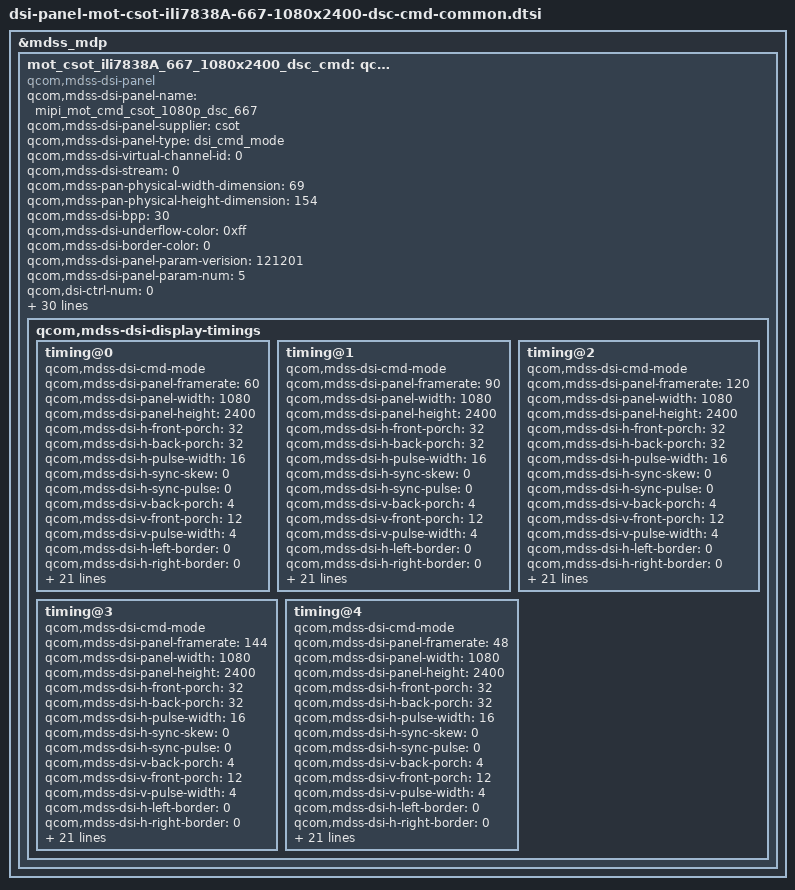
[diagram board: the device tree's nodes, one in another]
/* Copyright (c) 2019-2020, The Linux Foundation. All rights reserved.
 *
 * This program is free software; you can redistribute it and/or modify
 * it under the terms of the GNU General Public License version 2 and
 * only version 2 as published by the Free Software Foundation.
 *
 * This program is distributed in the hope that it will be useful,
 * but WITHOUT ANY WARRANTY; without even the implied warranty of
 * MERCHANTABILITY or FITNESS FOR A PARTICULAR PURPOSE.  See the
 * GNU General Public License for more details.
 */
&mdss_mdp {
mot_csot_ili7838A_667_1080x2400_dsc_cmd: qcom,mdss_dsi_mot_csot_ili7838A_667_1080x2400_dsc_cmd {
compatible = "qcom,mdss-dsi-panel";
qcom,mdss-dsi-panel-name = "mipi_mot_cmd_csot_1080p_dsc_667";
qcom,mdss-dsi-panel-supplier = "csot";
qcom,mdss-dsi-panel-type = "dsi_cmd_mode";
qcom,mdss-dsi-virtual-channel-id = <0>;
qcom,mdss-dsi-stream = <0>;
qcom,mdss-pan-physical-width-dimension = <69>;
qcom,mdss-pan-physical-height-dimension = <154>;
qcom,mdss-dsi-bpp = <30>;
qcom,mdss-dsi-underflow-color = <0xff>;
qcom,mdss-dsi-border-color = <0>;
qcom,mdss-dsi-panel-param-verision = <121201>;
qcom,mdss-dsi-panel-param-num = <5>;

qcom,dsi-ctrl-num = <0>;
qcom,dsi-phy-num = <0>;

qcom,mdss-dsi-traffic-mode = "burst_mode";
qcom,mdss-dsi-bllp-eof-power-mode;
qcom,mdss-dsi-bllp-power-mode;
qcom,mdss-dsi-lane-0-state;
qcom,mdss-dsi-lane-1-state;
qcom,mdss-dsi-lane-2-state;
qcom,mdss-dsi-lane-3-state;

qcom,mdss-dsi-dma-trigger = "trigger_sw";
qcom,mdss-dsi-mdp-trigger = "none";
qcom,mdss-dsi-reset-sequence = <0 11>, <1 1>, <0 1>, <1 11>;
qcom,mdss-dsi-lp11-init;
qcom,mdss-dsi-tx-eot-append;
qcom,mdss-dsi-te-pin-select = <1>;
qcom,mdss-dsi-te-dcs-command = <1>;
qcom,mdss-dsi-te-using-te-pin;

//qcom,bklt-dcs-2bytes-enabled;
qcom,mdss-dsi-bl-min-level = <3>;
qcom,mdss-dsi-bl-max-level = <2047>;
qcom,mdss-dsi-bl-pmic-control-type = "bl_ctrl_dcs";

qcom,mdss-dsi-panel-hdr-enabled;
qcom,mdss-dsi-panel-hdr-color-primaries = <14500 15500 32000
	        17000 15500 30000 8000 3000>;
qcom,mdss-dsi-panel-peak-brightness = <4200000>;

qcom,mdss-dsi-panel-blackness-level = <3230>;

qcom,mdss-dsi-hbm-on-command = [
		39 01 00 00 00 00 03 51 0F FF];
qcom,mdss-dsi-hbm-off-command = [
		39 01 00 00 00 00 03 51 07 FF];

//qcom,mdss-dsi-acl-on-command = [
//		39 01 00 00 00 00 06 F0 55 AA 52 08 00
//		15 00 00 00 00 00 02 B0 0C
//		15 01 00 00 00 00 02 55 05];
//qcom,mdss-dsi-acl-off-command = [
//		15 01 00 00 00 00 02 55 00];


qcom,mdss-dsi-display-timings {
	timing@0{
		qcom,mdss-dsi-cmd-mode;
		qcom,mdss-dsi-panel-framerate = <60>;
		qcom,mdss-dsi-panel-width = <1080>;
		qcom,mdss-dsi-panel-height = <2400>;
		qcom,mdss-dsi-h-front-porch = <32>;
		qcom,mdss-dsi-h-back-porch = <32>;
		qcom,mdss-dsi-h-pulse-width = <16>;
		qcom,mdss-dsi-h-sync-skew = <0>;
		qcom,mdss-dsi-h-sync-pulse = <0>;
		qcom,mdss-dsi-v-back-porch = <4>;
		qcom,mdss-dsi-v-front-porch = <12>;
		qcom,mdss-dsi-v-pulse-width = <4>;
		qcom,mdss-dsi-h-left-border = <0>;
		qcom,mdss-dsi-h-right-border = <0>;
		qcom,mdss-dsi-v-top-border = <0>;
		qcom,mdss-dsi-v-bottom-border = <0>;
		qcom,mdss-dsi-panel-jitter = <0x20 0xa>; /* 90fps +/- 2 */
		qcom,mdss-dsi-timing-switch-command = [
			39 01 00 00 00 00 04 FF 78 38 02 //60Hz
			39 01 00 00 00 00 02 38 23
			39 01 00 00 00 00 02 44 90
			39 01 00 00 00 00 02 45 09
			39 01 00 00 14 00 04 FF 78 38 00
		];

		qcom,mdss-dsi-on-command = [
			39 01 00 00 00 00 04 FF 78 38 0D
			39 01 00 00 00 00 02 03 4e
			39 01 00 00 00 00 02 04 52
			39 01 00 00 00 00 02 05 50
			39 01 00 00 00 00 02 06 1F
			39 01 00 00 00 00 04 FF 78 38 08
			39 01 00 00 00 00 02 45 4C
			39 01 00 00 00 00 04 ff 78 38 07
			39 01 00 00 00 00 02 29 01
			39 01 00 00 00 00 04 FF 78 38 0D
			39 01 00 00 00 00 02 03 4E
			39 01 00 00 00 00 02 04 54
			39 01 00 00 00 00 02 05 50
			39 01 00 00 00 00 02 06 1F
			39 01 00 00 00 00 02 0E 16
			39 01 00 00 00 00 02 0F 69
			39 01 00 00 00 00 02 10 81
			39 01 00 00 00 00 02 11 01
			39 01 00 00 00 00 02 12 01
			39 01 00 00 00 00 02 13 44
			39 01 00 00 00 00 02 14 33
			39 01 00 00 00 00 02 15 00
			39 01 00 00 00 00 04 FF 78 38 06
			39 01 00 00 00 00 02 C7 00
			39 01 00 00 00 00 04 FF 78 38 0F
			39 01 00 00 00 00 02 C8 78
			39 01 00 00 00 00 02 C9 46
			39 01 00 00 00 00 04 FF 78 38 02 //60Hz
			39 01 00 00 00 00 02 38 23
			39 01 00 00 00 00 02 44 90
			39 01 00 00 00 00 02 45 09
			39 01 00 00 00 00 04 FF 78 38 00
			39 01 00 00 00 00 02 53 20
			39 01 00 00 00 00 03 51 00 00
			15 01 00 00 00 00 02 35 00

			05 01 00 00 0A 00 01 11
			05 01 00 00 78 00 01 29];	/* display on */
		qcom,mdss-dsi-off-command = [
			39 01 00 00 10 00 04 FF 78 38 00
			05 01 00 00 16 00 01 28		/* display_off */
			05 01 00 00 78 00 01 10];	/* enter sleep mode */

		qcom,mdss-dsi-on-command-state = "dsi_lp_mode";
		qcom,mdss-dsi-off-command-state = "dsi_lp_mode";
		qcom,mdss-dsi-timing-switch-command-state =
			"dsi_lp_mode";
		qcom,compression-mode = "dsc";
		/* Why QCOM doesn't use this, even it used 2 encoder
		 * as for that dsi_sw43404_amoled_cmd, for ex */
		/* qcom,mdss-dsc-encoders = <2>; */
		qcom,mdss-dsc-version = <0x11>;
		qcom,mdss-dsc-slice-height = <12>;
		qcom,mdss-dsc-slice-width = <1080>;
		qcom,mdss-dsc-slice-per-pkt = <1>;
		qcom,mdss-dsc-bit-per-component = <10>;
		qcom,mdss-dsc-bit-per-pixel = <8>;
		qcom,mdss-dsc-block-prediction-enable;
	};
	timing@1{
		qcom,mdss-dsi-cmd-mode;
		qcom,mdss-dsi-panel-framerate = <90>;
		qcom,mdss-dsi-panel-width = <1080>;
		qcom,mdss-dsi-panel-height = <2400>;
		qcom,mdss-dsi-h-front-porch = <32>;
		qcom,mdss-dsi-h-back-porch = <32>;
		qcom,mdss-dsi-h-pulse-width = <16>;
		qcom,mdss-dsi-h-sync-skew = <0>;
		qcom,mdss-dsi-h-sync-pulse = <0>;
		qcom,mdss-dsi-v-back-porch = <4>;
		qcom,mdss-dsi-v-front-porch = <12>;
		qcom,mdss-dsi-v-pulse-width = <4>;
		qcom,mdss-dsi-h-left-border = <0>;
		qcom,mdss-dsi-h-right-border = <0>;
		qcom,mdss-dsi-v-top-border = <0>;
		qcom,mdss-dsi-v-bottom-border = <0>;
		qcom,mdss-dsi-panel-jitter = <0x20 0xa>; /* 90fps +/- 2 */
		qcom,mdss-dsi-timing-switch-command = [
			39 01 00 00 00 00 04 FF 78 38 02 //90Hz
			39 01 00 00 00 00 02 38 22
			39 01 00 00 00 00 02 42 30
			39 01 00 00 00 00 02 43 03
			39 01 00 00 14 00 04 FF 78 38 00
		];
		qcom,mdss-dsi-on-command = [
			39 01 00 00 00 00 04 FF 78 38 0D
			39 01 00 00 00 00 02 03 4e
			39 01 00 00 00 00 02 04 52
			39 01 00 00 00 00 02 05 50
			39 01 00 00 00 00 02 06 1F
			39 01 00 00 00 00 04 FF 78 38 08
			39 01 00 00 00 00 02 45 4C
			39 01 00 00 00 00 04 ff 78 38 07
			39 01 00 00 00 00 02 29 01
			39 01 00 00 00 00 04 FF 78 38 0D
			39 01 00 00 00 00 02 03 4E
			39 01 00 00 00 00 02 04 54
			39 01 00 00 00 00 02 05 50
			39 01 00 00 00 00 02 06 1F
			39 01 00 00 00 00 02 0E 16
			39 01 00 00 00 00 02 0F 69
			39 01 00 00 00 00 02 10 81
			39 01 00 00 00 00 02 11 01
			39 01 00 00 00 00 02 12 01
			39 01 00 00 00 00 02 13 44
			39 01 00 00 00 00 02 14 33
			39 01 00 00 00 00 02 15 00
			39 01 00 00 00 00 04 FF 78 38 06
			39 01 00 00 00 00 02 C7 00
			39 01 00 00 00 00 04 FF 78 38 0F
			39 01 00 00 00 00 02 C8 78
			39 01 00 00 00 00 02 C9 46

			39 01 00 00 00 00 04 FF 78 38 02 //90Hz
			39 01 00 00 00 00 02 38 22
			39 01 00 00 00 00 02 42 30
			39 01 00 00 00 00 02 43 03

			39 01 00 00 00 00 04 FF 78 38 00
			39 01 00 00 00 00 02 53 20
			39 01 00 00 00 00 03 51 00 00
			15 01 00 00 00 00 02 35 00

			05 01 00 00 0A 00 01 11
			05 01 00 00 78 00 01 29];	/* display on */
		qcom,mdss-dsi-off-command = [
			39 01 00 00 10 00 04 FF 78 38 00
			05 01 00 00 16 00 01 28		/* display_off */
			05 01 00 00 78 00 01 10];	/* enter sleep mode */

		qcom,mdss-dsi-on-command-state = "dsi_lp_mode";
		qcom,mdss-dsi-off-command-state = "dsi_lp_mode";
		qcom,mdss-dsi-timing-switch-command-state =
			"dsi_lp_mode";
		qcom,compression-mode = "dsc";
		/* Why QCOM doesn't use this, even it used 2 encoder
		 * as for that dsi_sw43404_amoled_cmd, for ex */
		/* qcom,mdss-dsc-encoders = <2>; */
		qcom,mdss-dsc-version = <0x11>;
		qcom,mdss-dsc-slice-height = <12>;
		qcom,mdss-dsc-slice-width = <1080>;
		qcom,mdss-dsc-slice-per-pkt = <1>;
		qcom,mdss-dsc-bit-per-component = <10>;
		qcom,mdss-dsc-bit-per-pixel = <8>;
		qcom,mdss-dsc-block-prediction-enable;
	};
	timing@2{
		qcom,mdss-dsi-cmd-mode;
		qcom,mdss-dsi-panel-framerate = <120>;
		qcom,mdss-dsi-panel-width = <1080>;
		qcom,mdss-dsi-panel-height = <2400>;
		qcom,mdss-dsi-h-front-porch = <32>;
		qcom,mdss-dsi-h-back-porch = <32>;
		qcom,mdss-dsi-h-pulse-width = <16>;
		qcom,mdss-dsi-h-sync-skew = <0>;
		qcom,mdss-dsi-h-sync-pulse = <0>;
		qcom,mdss-dsi-v-back-porch = <4>;
		qcom,mdss-dsi-v-front-porch = <12>;
		qcom,mdss-dsi-v-pulse-width = <4>;
		qcom,mdss-dsi-h-left-border = <0>;
		qcom,mdss-dsi-h-right-border = <0>;
		qcom,mdss-dsi-v-top-border = <0>;
		qcom,mdss-dsi-v-bottom-border = <0>;
		qcom,mdss-dsi-panel-jitter = <0x20 0xa>; /* 90fps +/- 2 */
		qcom,mdss-dsi-timing-switch-command = [
			39 01 00 00 00 00 04 FF 78 38 02 //120Hz
			39 01 00 00 00 00 02 38 22
			39 01 00 00 00 00 02 42 00
			39 01 00 00 00 00 02 43 00
			39 01 00 00 14 00 04 FF 78 38 00
		];
		qcom,mdss-dsi-on-command = [
			39 01 00 00 00 00 04 FF 78 38 0D
			39 01 00 00 00 00 02 03 4e
			39 01 00 00 00 00 02 04 52
			39 01 00 00 00 00 02 05 50
			39 01 00 00 00 00 02 06 1F
			39 01 00 00 00 00 04 FF 78 38 08
			39 01 00 00 00 00 02 45 4C
			39 01 00 00 00 00 04 ff 78 38 07
			39 01 00 00 00 00 02 29 01
			39 01 00 00 00 00 04 FF 78 38 0D
			39 01 00 00 00 00 02 03 4E
			39 01 00 00 00 00 02 04 54
			39 01 00 00 00 00 02 05 50
			39 01 00 00 00 00 02 06 1F
			39 01 00 00 00 00 02 0E 16
			39 01 00 00 00 00 02 0F 69
			39 01 00 00 00 00 02 10 81
			39 01 00 00 00 00 02 11 01
			39 01 00 00 00 00 02 12 01
			39 01 00 00 00 00 02 13 44
			39 01 00 00 00 00 02 14 33
			39 01 00 00 00 00 02 15 00
			39 01 00 00 00 00 04 FF 78 38 06
			39 01 00 00 00 00 02 C7 00
			39 01 00 00 00 00 04 FF 78 38 0F
			39 01 00 00 00 00 02 C8 78
			39 01 00 00 00 00 02 C9 46
			39 01 00 00 00 00 04 FF 78 38 02 //120Hz
			39 01 00 00 00 00 02 38 22
			39 01 00 00 00 00 02 42 00
			39 01 00 00 00 00 02 43 00
			39 01 00 00 00 00 04 FF 78 38 00
			39 01 00 00 00 00 02 53 20
			39 01 00 00 00 00 03 51 00 00
			15 01 00 00 00 00 02 35 00

			05 01 00 00 0A 00 01 11
			05 01 00 00 78 00 01 29];	/* display on */
		qcom,mdss-dsi-off-command = [
			39 01 00 00 10 00 04 FF 78 38 00
			05 01 00 00 16 00 01 28		/* display_off */
			05 01 00 00 78 00 01 10];	/* enter sleep mode */

		qcom,mdss-dsi-on-command-state = "dsi_lp_mode";
		qcom,mdss-dsi-off-command-state = "dsi_lp_mode";
		qcom,mdss-dsi-timing-switch-command-state =
			"dsi_lp_mode";
		qcom,compression-mode = "dsc";
		/* Why QCOM doesn't use this, even it used 2 encoder
		 * as for that dsi_sw43404_amoled_cmd, for ex */
		/* qcom,mdss-dsc-encoders = <2>; */
		qcom,mdss-dsc-version = <0x11>;
		qcom,mdss-dsc-slice-height = <12>;
		qcom,mdss-dsc-slice-width = <1080>;
		qcom,mdss-dsc-slice-per-pkt = <1>;
		qcom,mdss-dsc-bit-per-component = <10>;
		qcom,mdss-dsc-bit-per-pixel = <8>;
		qcom,mdss-dsc-block-prediction-enable;
	};
	timing@3{
		qcom,mdss-dsi-cmd-mode;
		qcom,mdss-dsi-panel-framerate = <144>;
		qcom,mdss-dsi-panel-width = <1080>;
		qcom,mdss-dsi-panel-height = <2400>;
		qcom,mdss-dsi-h-front-porch = <32>;
		qcom,mdss-dsi-h-back-porch = <32>;
		qcom,mdss-dsi-h-pulse-width = <16>;
		qcom,mdss-dsi-h-sync-skew = <0>;
		qcom,mdss-dsi-h-sync-pulse = <0>;
		qcom,mdss-dsi-v-back-porch = <4>;
		qcom,mdss-dsi-v-front-porch = <12>;
		qcom,mdss-dsi-v-pulse-width = <4>;
		qcom,mdss-dsi-h-left-border = <0>;
		qcom,mdss-dsi-h-right-border = <0>;
		qcom,mdss-dsi-v-top-border = <0>;
		qcom,mdss-dsi-v-bottom-border = <0>;
		qcom,mdss-dsi-panel-jitter = <0x20 0xa>; /* 90fps +/- 2 */
		qcom,mdss-dsi-timing-switch-command = [
			39 01 00 00 00 00 04 FF 78 38 02 //144Hz
			39 01 00 00 00 00 02 38 21
			39 01 00 00 14 00 04 FF 78 38 00
		];
		qcom,mdss-dsi-on-command = [
			39 01 00 00 00 00 04 FF 78 38 0D
			39 01 00 00 00 00 02 03 4e
			39 01 00 00 00 00 02 04 52
			39 01 00 00 00 00 02 05 50
			39 01 00 00 00 00 02 06 1F
			39 01 00 00 00 00 04 FF 78 38 08
			39 01 00 00 00 00 02 45 4C
			39 01 00 00 00 00 04 ff 78 38 07
			39 01 00 00 00 00 02 29 01
			39 01 00 00 00 00 04 FF 78 38 0D
			39 01 00 00 00 00 02 03 4E
			39 01 00 00 00 00 02 04 54
			39 01 00 00 00 00 02 05 50
			39 01 00 00 00 00 02 06 1F
			39 01 00 00 00 00 02 0E 16
			39 01 00 00 00 00 02 0F 69
			39 01 00 00 00 00 02 10 81
			39 01 00 00 00 00 02 11 01
			39 01 00 00 00 00 02 12 01
			39 01 00 00 00 00 02 13 44
			39 01 00 00 00 00 02 14 33
			39 01 00 00 00 00 02 15 00
			39 01 00 00 00 00 04 FF 78 38 06
			39 01 00 00 00 00 02 C7 00
			39 01 00 00 00 00 04 FF 78 38 0F
			39 01 00 00 00 00 02 C8 78
			39 01 00 00 00 00 02 C9 46
			39 01 00 00 00 00 04 FF 78 38 02 //144Hz
			39 01 00 00 00 00 02 38 21
			39 01 00 00 00 00 04 FF 78 38 00
			39 01 00 00 00 00 02 53 20
			39 01 00 00 00 00 03 51 00 00
			15 01 00 00 00 00 02 35 00

			05 01 00 00 0A 00 01 11
			05 01 00 00 78 00 01 29];	/* display on */
		qcom,mdss-dsi-off-command = [
			39 01 00 00 10 00 04 FF 78 38 00
			05 01 00 00 16 00 01 28		/* display_off */
			05 01 00 00 78 00 01 10];	/* enter sleep mode */

		qcom,mdss-dsi-on-command-state = "dsi_lp_mode";
		qcom,mdss-dsi-off-command-state = "dsi_lp_mode";
		qcom,mdss-dsi-timing-switch-command-state =
			"dsi_lp_mode";
		qcom,compression-mode = "dsc";
		/* Why QCOM doesn't use this, even it used 2 encoder
		 * as for that dsi_sw43404_amoled_cmd, for ex */
		/* qcom,mdss-dsc-encoders = <2>; */
		qcom,mdss-dsc-version = <0x11>;
		qcom,mdss-dsc-slice-height = <12>;
		qcom,mdss-dsc-slice-width = <1080>;
		qcom,mdss-dsc-slice-per-pkt = <1>;
		qcom,mdss-dsc-bit-per-component = <10>;
		qcom,mdss-dsc-bit-per-pixel = <8>;
		qcom,mdss-dsc-block-prediction-enable;
	};
	timing@4{
		qcom,mdss-dsi-cmd-mode;
		qcom,mdss-dsi-panel-framerate = <48>;
		qcom,mdss-dsi-panel-width = <1080>;
		qcom,mdss-dsi-panel-height = <2400>;
		qcom,mdss-dsi-h-front-porch = <32>;
		qcom,mdss-dsi-h-back-porch = <32>;
		qcom,mdss-dsi-h-pulse-width = <16>;
		qcom,mdss-dsi-h-sync-skew = <0>;
		qcom,mdss-dsi-h-sync-pulse = <0>;
		qcom,mdss-dsi-v-back-porch = <4>;
		qcom,mdss-dsi-v-front-porch = <12>;
		qcom,mdss-dsi-v-pulse-width = <4>;
		qcom,mdss-dsi-h-left-border = <0>;
		qcom,mdss-dsi-h-right-border = <0>;
		qcom,mdss-dsi-v-top-border = <0>;
		qcom,mdss-dsi-v-bottom-border = <0>;
		qcom,mdss-dsi-panel-jitter = <0x20 0xa>; /* 90fps +/- 2 */
		qcom,mdss-dsi-timing-switch-command = [
			39 01 00 00 00 00 04 FF 78 38 02 //48Hz
			39 01 00 00 00 00 02 38 23
			39 01 00 00 00 00 02 44 58
			39 01 00 00 00 00 02 45 0e
			39 01 00 00 14 00 04 FF 78 38 00
		];
		qcom,mdss-dsi-on-command = [
			39 01 00 00 00 00 04 FF 78 38 0D
			39 01 00 00 00 00 02 03 4e
			39 01 00 00 00 00 02 04 52
			39 01 00 00 00 00 02 05 50
			39 01 00 00 00 00 02 06 1F
			39 01 00 00 00 00 04 FF 78 38 08
			39 01 00 00 00 00 02 45 4C
			39 01 00 00 00 00 04 ff 78 38 07
			39 01 00 00 00 00 02 29 01
			39 01 00 00 00 00 04 FF 78 38 0D
			39 01 00 00 00 00 02 03 4E
			39 01 00 00 00 00 02 04 54
			39 01 00 00 00 00 02 05 50
			39 01 00 00 00 00 02 06 1F
			39 01 00 00 00 00 02 0E 16
			39 01 00 00 00 00 02 0F 69
			39 01 00 00 00 00 02 10 81
			39 01 00 00 00 00 02 11 01
			39 01 00 00 00 00 02 12 01
			39 01 00 00 00 00 02 13 44
			39 01 00 00 00 00 02 14 33
			39 01 00 00 00 00 02 15 00
			39 01 00 00 00 00 04 FF 78 38 06
			39 01 00 00 00 00 02 C7 00
			39 01 00 00 00 00 04 FF 78 38 0F
			39 01 00 00 00 00 02 C8 78
			39 01 00 00 00 00 02 C9 46
			39 01 00 00 00 00 04 FF 78 38 02 //48Hz
			39 01 00 00 00 00 02 38 23
			39 01 00 00 00 00 02 44 58
			39 01 00 00 00 00 02 45 0e
			39 01 00 00 00 00 04 FF 78 38 00
			39 01 00 00 00 00 02 53 20
			39 01 00 00 00 00 03 51 00 00
			15 01 00 00 00 00 02 35 00

			05 01 00 00 0A 00 01 11
			05 01 00 00 78 00 01 29];	/* display on */
		qcom,mdss-dsi-off-command = [
			39 01 00 00 10 00 04 FF 78 38 00
			05 01 00 00 16 00 01 28		/* display_off */
			05 01 00 00 78 00 01 10];	/* enter sleep mode */

		qcom,mdss-dsi-on-command-state = "dsi_lp_mode";
		qcom,mdss-dsi-off-command-state = "dsi_lp_mode";
		qcom,mdss-dsi-timing-switch-command-state =
			"dsi_lp_mode";
		qcom,compression-mode = "dsc";
		/* Why QCOM doesn't use this, even it used 2 encoder
		 * as for that dsi_sw43404_amoled_cmd, for ex */
		/* qcom,mdss-dsc-encoders = <2>; */
		qcom,mdss-dsc-version = <0x11>;
		qcom,mdss-dsc-slice-height = <12>;
		qcom,mdss-dsc-slice-width = <1080>;
		qcom,mdss-dsc-slice-per-pkt = <1>;
		qcom,mdss-dsc-bit-per-component = <10>;
		qcom,mdss-dsc-bit-per-pixel = <8>;
		qcom,mdss-dsc-block-prediction-enable;
	};

};

};

};
